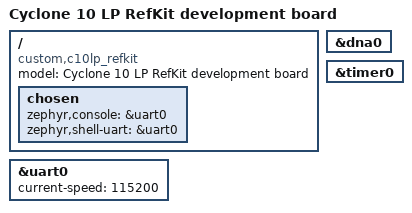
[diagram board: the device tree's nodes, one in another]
/dts-v1/;

#include <c10lp_refkit_soc.dtsi>

/ {

  model = "Cyclone 10 LP RefKit development board";
  compatible = "custom,c10lp_refkit";

  chosen {
    zephyr,console = &uart0;
    zephyr,shell-uart = &uart0;
  };

};

&dna0 {
  status = "okay";
};

&uart0 {
  status = "okay";
  current-speed = <115200>;
};

&timer0 {
  status = "okay";
};
